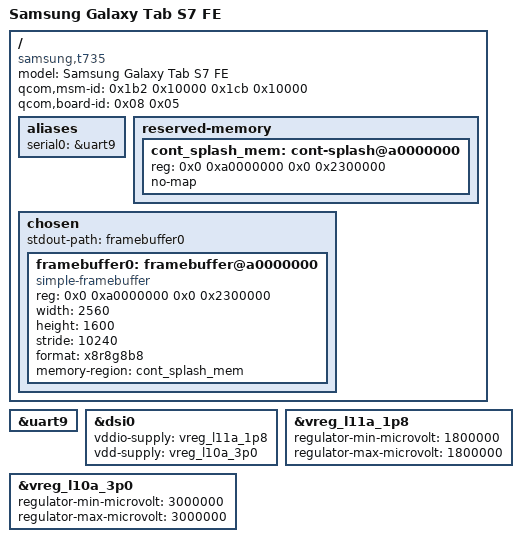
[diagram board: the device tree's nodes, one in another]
// SPDX-License-Identifier: BSD-3-Clause
/*
 * Copyright (c) 2026, Rakan Badawood <rakzn> 
 */

/dts-v1/;

#include "sm7225.dtsi"
#include "pm6150.dtsi"
#include "pm6150l.dtsi"

/ {
	model = "Samsung Galaxy Tab S7 FE";
	compatible = "samsung,t735", "qcom,sm7225";

	/* 1. Added battery dump */
	qcom,msm-id = <0x1b2 0x10000 0x1cb 0x10000>;
	qcom,board-id = <0x08 0x05>;

	aliases {
		serial0 = &uart9;
	};

	/* 2. Added Reserved Memory to protect the display buffer */
	reserved-memory {
		#address-cells = <2>;
		#size-cells = <2>;
		ranges;

		cont_splash_mem: cont-splash@a0000000 {
			reg = <0x0 0xa0000000 0x0 0x2300000>;
			no-map;
		};
	};

	chosen {
		/* 3. Set output to screen (framebuffer) per pem120's advice */
		stdout-path = "framebuffer0";

		#address-cells = <2>;
		#size-cells = <2>;
		ranges;

		framebuffer0: framebuffer@a0000000 {
			compatible = "simple-framebuffer";
			reg = <0x0 0xa0000000 0x0 0x2300000>;
			width = <2560>;
			height = <1600>;
			stride = <10240>;
			format = "x8r8g8b8";
			/* Link to the reserved memory node above */
			memory-region = <&cont_splash_mem>;
		};
	};
};

&uart9 {
	status = "okay";
};

/* Regulator config for the display rails */
&dsi0 {
	vddio-supply = <&vreg_l11a_1p8>;
	vdd-supply = <&vreg_l10a_3p0>;
};

&vreg_l11a_1p8 {
	regulator-min-microvolt = <1800000>;
	regulator-max-microvolt = <1800000>;
};

&vreg_l10a_3p0 {
	regulator-min-microvolt = <3000000>;
	regulator-max-microvolt = <3000000>;
};
